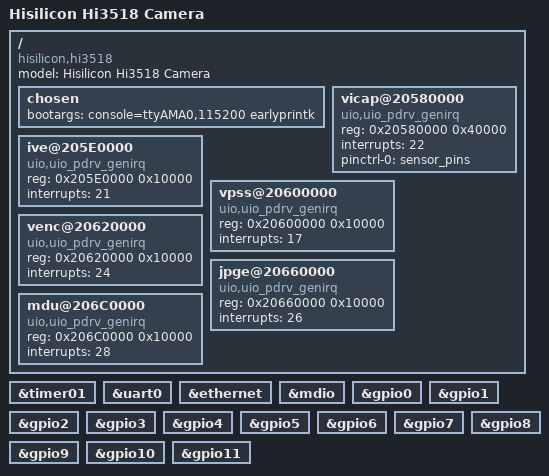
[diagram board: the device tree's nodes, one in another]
/*
 * Copyright (c) 2015 Robert Lukierski.
 * Copyright (c) 2013-2014 Linaro Ltd.
 * Copyright (c) 2013-2014 Hisilicon Limited.
 *
 *  This program is free software; you can redistribute it and/or modify
 *  it under the terms of the GNU General Public License version 2 as
 *  publishhed by the Free Software Foundation.
 */

/dts-v1/;
#include "hisi-3518.dtsi"

/ {
    model = "Hisilicon Hi3518 Camera";
    compatible = "hisilicon,hi3518";

    chosen {
        bootargs = "console=ttyAMA0,115200 earlyprintk";
    };
    
    /* UIO devices (for now) */
    /* Video capture, includes ISP registers (0x205A0000) */
    vicap@20580000 {
        compatible = "uio,uio_pdrv_genirq", "generic-uio";
        reg = <0x20580000 0x40000>;
        reg-names = "io";
        interrupts = <22>;
        
        pinctrl-names = "default";
        pinctrl-0 = <&sensor_pins>;
        
        status = "okay";
    };
    
    /* Intelligent Video Engine */
    ive@205E0000 {
        compatible = "uio,uio_pdrv_genirq", "generic-uio";
        reg = <0x205E0000 0x10000>;
        reg-names = "io";
        interrupts = <21>;
        status = "okay";
    };
    
    /* Video Processing Subsystem */
    vpss@20600000 {
        compatible = "uio,uio_pdrv_genirq", "generic-uio";
        reg = <0x20600000 0x10000>;
        interrupts = <17>;
        status = "okay";
    };
    
    /* MPEG Encoder */
    venc@20620000 {
        compatible = "uio,uio_pdrv_genirq", "generic-uio";
        reg = <0x20620000 0x10000>;
        interrupts = <24>;
        status = "okay";
    };
    
    /* JPEG Encoder */
    jpge@20660000 {
        compatible = "uio,uio_pdrv_genirq", "generic-uio";
        reg = <0x20660000 0x10000>;
        interrupts = <26>;
        status = "okay";
    };
    
    /* Motion Detection Unit */
    mdu@206C0000 {
        compatible = "uio,uio_pdrv_genirq", "generic-uio";
        reg = <0x206C0000 0x10000>;
        interrupts = <28>;
        status = "okay";
    };
};

&timer01 {
    status = "okay"; 
};

&uart0 {
    status = "okay";
};

&ethernet {
    status = "okay";
};

&mdio {
    status = "okay";
};

&gpio0 {
    status = "okay";
};

&gpio1 {
    status = "okay";
};

&gpio2 {
    status = "okay";
};

&gpio3 {
    status = "okay";
};

&gpio4 {
    status = "okay";
};

&gpio5 {
    status = "okay";
};

&gpio6 {
    status = "okay";
};

&gpio7 {
    status = "okay";
};

&gpio8 {
    status = "okay";
};

&gpio9 {
    status = "okay";
};

&gpio10 {
    status = "okay";
};

&gpio11 {
    status = "okay";
};

/*
&uart1 {
    status = "okay";
};

&uart2 {
    status = "okay";
};

&wdt {
    status = "okay";
};

&dmac {
    status = "okay";
};

&spi0 {
    status = "okay";
};

&spi1 {
    status = "okay";
};

&usb_ehci {
    status = "okay";
};

&usb_ohci {
    status = "okay";
};

&ir {
    status = "okay";
};

&i2c {
    status = "okay";
    
    eeprom: eeprom@50 
    { 
        compatible = "atmel,24c08"; 
        reg = <0x50>; 
        pagesize = <16>; 
    };
};

&sdio {
    status = "okay";
};
*/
